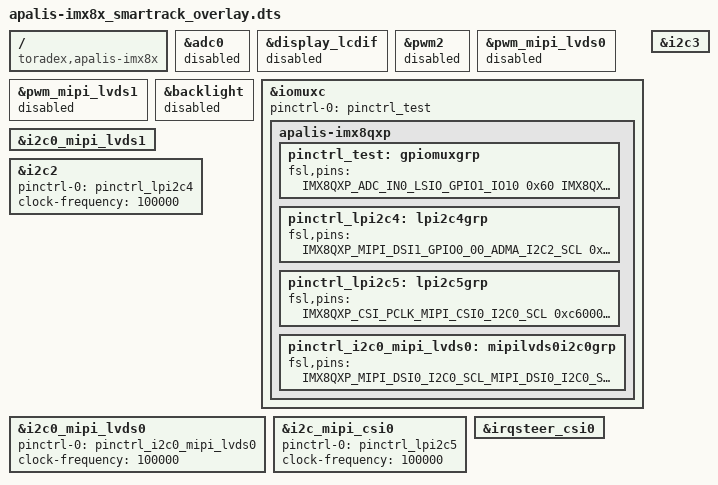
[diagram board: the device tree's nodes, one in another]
/dts-v1/;
/plugin/;

#include <dt-bindings/pinctrl/pads-imx8qxp.h>

/ {
    compatible = "toradex,apalis-imx8x";

    /* GPIO: 305, 307, 309, 311 */
    /* NOT GPIO: none */
    /* pinctrl_adc0 */
    fragment@0 {
        target = <&adc0>;
        __overlay__ {
            status = "disabled";
        };
    };

    /* GPIO: 243, 245, 247, 255, 257, 259, 261, 265 */
    /* NOT GPIO: 249, 263, 273, 275, 277, 279, 281, 283, 291, 293, 295, 297, 299, 301 */
    /* pinctrl_lcdif */
    fragment@1 {
        target = <&display_lcdif>;
        __overlay__ {
            status = "disabled";
        };
    };

    /* GPIO: 2 */
    /* NOT GPIO: none */
    /* pinctrl_pwm2 */
    fragment@2 {
        target = <&pwm2>;
        __overlay__ {
            status = "disabled";
        };
    };

    /* GPIO: none */
    /* NOT GPIO: 4 */
    /* pinctrl_pwm_mipi_lvds0 */
    fragment@3 {
        target = <&pwm_mipi_lvds0>;
        __overlay__ {
            status = "disabled";
        };
    };

    /* GPIO: none */
    /* NOT GPIO: 239 */
    /* pinctrl_pwm_mipi_lvds1 */
    fragment@4 {
        target = <&pwm_mipi_lvds1>;
        __overlay__ {
            status = "disabled";
        };
    };

    /* GPIO: 286 */
    /* NOT GPIO: none */
    /* pinctrl_gpio_bkl_on */
    fragment@5 {
        target = <&backlight>;
        __overlay__ {
            status = "disabled";
        };
    };

    fragment@6 {
        target = <&iomuxc>;
        __overlay__ {
            pinctrl-names = "default";
            pinctrl-0 = <&pinctrl_test>;
            apalis-imx8qxp {
                pinctrl_test: gpiomuxgrp {
                    fsl,pins = <
                        IMX8QXP_ADC_IN0_LSIO_GPIO1_IO10        0x60 /* MXM3 305 */
                        IMX8QXP_ADC_IN1_LSIO_GPIO1_IO09        0x60 /* MXM3 307 */
                        IMX8QXP_ADC_IN4_LSIO_GPIO1_IO14        0x60 /* MXM3 309 */
                        IMX8QXP_ADC_IN5_LSIO_GPIO1_IO13        0x60 /* MXM3 311 */
                        IMX8QXP_MCLK_OUT0_LSIO_GPIO0_IO20      0x60 /* MXM3 243 */
                        IMX8QXP_MCLK_IN0_LSIO_GPIO0_IO19       0x60 /* MXM3 245 */
                        IMX8QXP_SPI3_CS0_LSIO_GPIO0_IO16       0x60 /* MXM3 247 */
                        IMX8QXP_SPDIF0_EXT_CLK_LSIO_GPIO0_IO12 0x60 /* MXM3 255 */
                        IMX8QXP_SPI3_SCK_LSIO_GPIO0_IO13       0x60 /* MXM3 257 */
                        IMX8QXP_SPI3_SDO_LSIO_GPIO0_IO14       0x60 /* MXM3 259 */
                        IMX8QXP_SPI3_SDI_LSIO_GPIO0_IO15       0x60 /* MXM3 261 */
                        IMX8QXP_UART1_CTS_B_LSIO_GPIO0_IO24    0x60 /* MXM3 265 */
                        IMX8QXP_QSPI0A_DQS_LSIO_GPIO3_IO13     0x21 /* MXM3 286 */
                    >;
                };
                pinctrl_lpi2c4: lpi2c4grp {
                    fsl,pins = <
                        IMX8QXP_MIPI_DSI1_GPIO0_00_ADMA_I2C2_SCL 0xc6000020 /* MXM3 239 */
                        IMX8QXP_MIPI_DSI1_GPIO0_01_ADMA_I2C2_SDA 0xc6000020 /* MXM3 8 */
                    >;
                };
                pinctrl_lpi2c5: lpi2c5grp {
                    fsl,pins = <
                        IMX8QXP_CSI_PCLK_MIPI_CSI0_I2C0_SCL 0xc6000020 /* MXM3 191 */
                        IMX8QXP_CSI_MCLK_MIPI_CSI0_I2C0_SDA 0xc6000020 /* MXM3 193 */
                    >;
                };
                pinctrl_i2c0_mipi_lvds0: mipilvds0i2c0grp {
                    fsl,pins = <
                        IMX8QXP_MIPI_DSI0_I2C0_SCL_MIPI_DSI0_I2C0_SCL 0xc6000020 /* MXM3 35 */
                        IMX8QXP_MIPI_DSI0_I2C0_SDA_MIPI_DSI0_I2C0_SDA 0xc6000020 /* MXM3 37 */
                    >;
                };
            };
        };
    };

    /* I2C2: 205, 207 */
    fragment@7 {
        target = <&i2c0_mipi_lvds1>;
        __overlay__ {
            status = "okay";
        };
    };

    /* I2C3: 203, 201 */
    fragment@8 {
        target = <&i2c3>;
        __overlay__ {
            status = "okay";
        };
    };

    fragment@9 {
        target = <&i2c2>;
        __overlay__ {
            #address-cells = <1>;
            #size-cells = <0>;
            pinctrl-names = "default";
            pinctrl-0 = <&pinctrl_lpi2c4>;
            clock-frequency = <100000>;
            status = "okay";
        };
    };

    fragment@10 {
        target = <&i2c0_mipi_lvds0>;
        __overlay__ {
            #address-cells = <1>;
            #size-cells = <0>;
            pinctrl-names = "default";
            pinctrl-0 = <&pinctrl_i2c0_mipi_lvds0>;
            clock-frequency = <100000>;
            status = "okay";
        };
    };

    fragment@11 {
        target = <&i2c_mipi_csi0>;
        __overlay__ {
            #address-cells = <1>;
            #size-cells = <0>;
            pinctrl-names = "default";
            pinctrl-0 = <&pinctrl_lpi2c5>;
            clock-frequency = <100000>;
            status = "okay";
        };
    };

    /* Enable interrupt parent for i2c_mipi_csi0 */
    fragment@12 {
        target = <&irqsteer_csi0>;
        __overlay__ {
            status = "okay";
        };
    };
};
